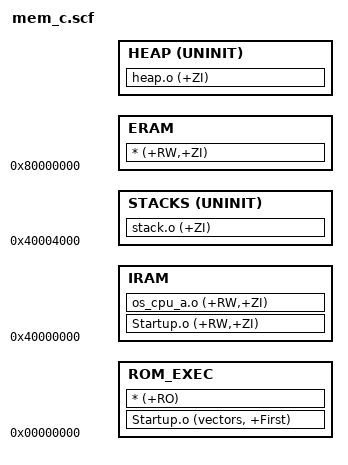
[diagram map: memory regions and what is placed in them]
;/****************************************Copyright (c)**************************************************
;**                               广州周立功单片机发展有限公司
;**                                     研    究    所
;**                                        产品一部 
;**
;**                                 http://www.zlgmcu.com
;**
;**--------------文件信息--------------------------------------------------------------------------------
;**文   件   名: mem_c.scf
;**创   建   人: 陈明计
;**最后修改日期: 2003年12月14日
;**描        述: 有片内FLASH分散加载文件，决定各个代码段和数据段的存储位置（用于产品）
;**              每个工程应当有独立的这个文件的拷贝，并进行相应的修改   
;**--------------历史版本信息----------------------------------------------------------------------------
;** 创建人: 陈明计
;** 版  本: v1.0
;** 日　期: 2003年12月14日
;** 描　述: 原始版本
;**
;**------------------------------------------------------------------------------------------------------
;** 修改人: 
;** 版  本: 
;** 日　期: 
;** 描　述: 
;**
;**--------------当前版本修订------------------------------------------------------------------------------
;** 修改人:
;** 日　期:
;** 描　述:
;**
;**------------------------------------------------------------------------------------------------------
;********************************************************************************************************/

ROM_LOAD 0x0
{
    ROM_EXEC 0x00000000
    {
        Startup.o (vectors, +First)
        * (+RO)
    }

    IRAM 0x40000000
    {
        Startup.o (+RW,+ZI)
        os_cpu_a.o (+RW,+ZI)
    }

    ERAM 0x80000000
    {
        * (+RW,+ZI)
    }

    HEAP +0 UNINIT
    {
        heap.o (+ZI)
    }

    STACKS 0x40004000 UNINIT
    {
        stack.o (+ZI)
    }
}

